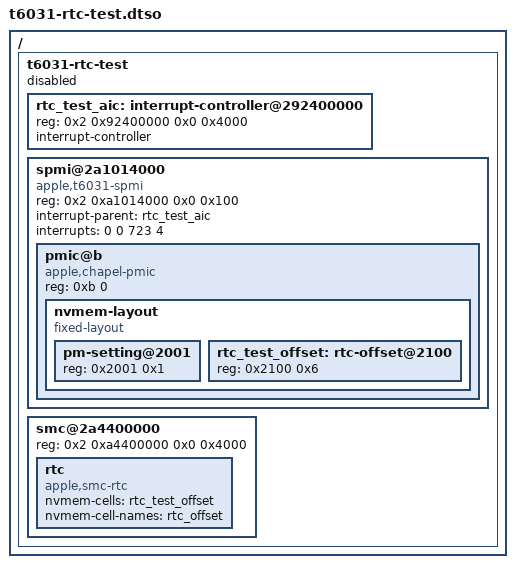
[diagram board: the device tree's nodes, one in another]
// SPDX-License-Identifier: GPL-2.0+ OR MIT
/*
 * Test device tree for the display gate's T6031 RTC alarm phase (KUnit):
 * the SPMI controller, PMU cells and SMC RTC of t6031-die0.dtsi as a boot
 * loader built before the RTC alarm passes them, the RTC with its offset
 * cell alone and the controller no interrupt controller.
 *
 * Its own root is disabled, so no device is created for any of these nodes.
 */

/dts-v1/;
/plugin/;

/ {
	fragment@0 {
		target-path = "/";

		__overlay__ {
			t6031-rtc-test {
				#address-cells = <2>;
				#size-cells = <2>;
				ranges = <0x2 0x0 0x2 0x0 0x1 0x0>;
				status = "disabled";

				rtc_test_aic: interrupt-controller@292400000 {
					reg = <0x2 0x92400000 0x0 0x4000>;
					interrupt-controller;
					#interrupt-cells = <4>;
				};

				spmi@2a1014000 {
					compatible = "apple,t6031-spmi", "apple,t8103-spmi";
					reg = <0x2 0xa1014000 0x0 0x100>;
					#address-cells = <2>;
					#size-cells = <0>;
					interrupt-parent = <&rtc_test_aic>;
					interrupts = <0 0 723 4>;

					pmic@b {
						compatible = "apple,chapel-pmic", "apple,spmi-nvmem";
						reg = <0xb 0>;

						nvmem-layout {
							compatible = "fixed-layout";
							#address-cells = <1>;
							#size-cells = <1>;

							pm-setting@2001 {
								reg = <0x2001 0x1>;
							};

							rtc_test_offset: rtc-offset@2100 {
								reg = <0x2100 0x6>;
							};
						};
					};
				};

				smc@2a4400000 {
					reg = <0x2 0xa4400000 0x0 0x4000>;

					rtc {
						compatible = "apple,smc-rtc";
						nvmem-cells = <&rtc_test_offset>;
						nvmem-cell-names = "rtc_offset";
					};
				};
			};
		};
	};
};
